# R7FA2A1AB register map
Vendor: Renesas; Series: RA2; File version: 1.1
CPU: CM23 r1p0, little endian, MPU, no FPU, VTOR, 2 interrupt priority bits
Registers are 8-bit, read-write, reset 0x0 unless marked. A register's access mark holds for its fields unless they carry their own. Offsets are from the block's base; [hi:lo] are bit positions; {n}, {i} and the like mark numbered series; 'fields as' and 'values as' point back to an identical list.

## CAN0 — CAN0 Module
Base 0x40050000
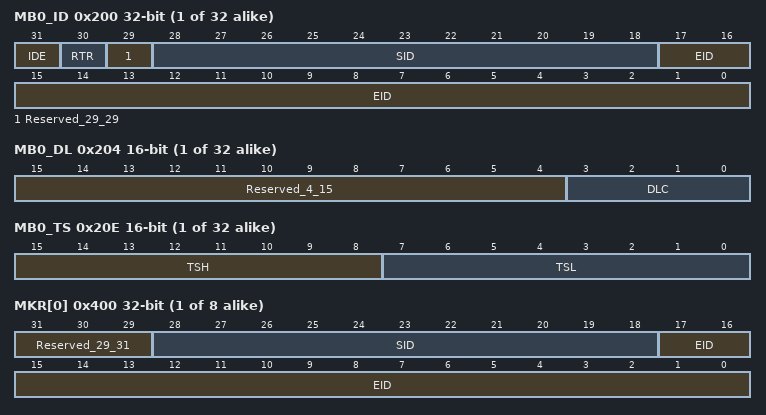
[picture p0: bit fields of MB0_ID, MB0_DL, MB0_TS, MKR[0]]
{0x200+0x10*i} MB{i}_ID (i=0..31) 32-bit reset not defined — Mailbox Register
  [31] IDE — ID Extension
  [30] RTR — Remote Transmission Request
  [29] Reserved_29_29 — This bit is read as 0. The write value should be 0.
  [28:18] SID — Standard ID
  [17:0] EID — Extended ID
{0x204+0x10*i} MB{i}_DL (i=0..31) 16-bit reset not defined — Mailbox Register
  [15:4] Reserved_4_15 — These bits are read as 000000000000. The write value should be 000000000000.
  [3:0] DLC — Data Length Code
{0x206+0x10*i} MB{i}_D0 (i=0..31) reset not defined — Mailbox Register
  [7:0] DATA0 — Data Bytes 0.DATA0 store the transmitted or received CAN message data. Transmission or reception starts from DATA0. The bit order on the CAN bus is MSB first, and transmission or reception starts from bit 7.
{0x207+0x10*i} MB{i}_D1 (i=0..31) reset not defined — Mailbox Register
  [7:0] DATA1 — Data Bytes 1DATA1 store the transmitted or received CAN message data. Transmission or reception starts from DATA0. The bit order on the CAN bus is MSB first, and transmission or reception starts from bit 7.
{0x208+0x10*i} MB{i}_D2 (i=0..31) reset not defined — Mailbox Register
  [7:0] DATA2 — Data Bytes 2DATA2 store the transmitted or received CAN message data. Transmission or reception starts from DATA0. The bit order on the CAN bus is MSB first, and transmission or reception starts from bit 7.
{0x209+0x10*i} MB{i}_D3 (i=0..31) reset not defined — Mailbox Register
  [7:0] DATA3 — Data Bytes 3DATA3 store the transmitted or received CAN message data. Transmission or reception starts from DATA0. The bit order on the CAN bus is MSB first, and transmission or reception starts from bit 7.
{0x20A+0x10*i} MB{i}_D4 (i=0..31) reset not defined — Mailbox Register
  [7:0] DATA4 — Data Bytes 4DATA4 store the transmitted or received CAN message data. Transmission or reception starts from DATA0. The bit order on the CAN bus is MSB first, and transmission or reception starts from bit 7.
{0x20B+0x10*i} MB{i}_D5 (i=0..31) reset not defined — Mailbox Register
  [7:0] DATA5 — Data Bytes 5DATA5 store the transmitted or received CAN message data. Transmission or reception starts from DATA0. The bit order on the CAN bus is MSB first, and transmission or reception starts from bit 7.
{0x20C+0x10*i} MB{i}_D6 (i=0..31) reset not defined — Mailbox Register
  [7:0] DATA6 — Data Bytes 6DATA6 store the transmitted or received CAN message data. Transmission or reception starts from DATA0. The bit order on the CAN bus is MSB first, and transmission or reception starts from bit 7.
{0x20D+0x10*i} MB{i}_D7 (i=0..31) reset not defined — Mailbox Register
  [7:0] DATA7 — Data Bytes 7DATA7 store the transmitted or received CAN message data. Transmission or reception starts from DATA0. The bit order on the CAN bus is MSB first, and transmission or reception starts from bit 7.
{0x20E+0x10*i} MB{i}_TS (i=0..31) 16-bit reset not defined — Mailbox Register
  [15:8] TSH — Time Stamp Lower ByteBits TSH[7:0] store the counter value of the time stamp when received messages are stored in the mailbox.
  [7:0] TSL — Time Stamp Higher ByteBits TSL[7:0] store the counter value of the time stamp when received messages are stored in the mailbox.
{0x400+4i} MKR[{i}] (i=0..7) 32-bit reset not defined — Mask Register
  [31:29] Reserved_29_31 — These bits are read as 000. The write value should be 000.
  [28:18] SID — Standard ID
  [17:0] EID — Extended ID
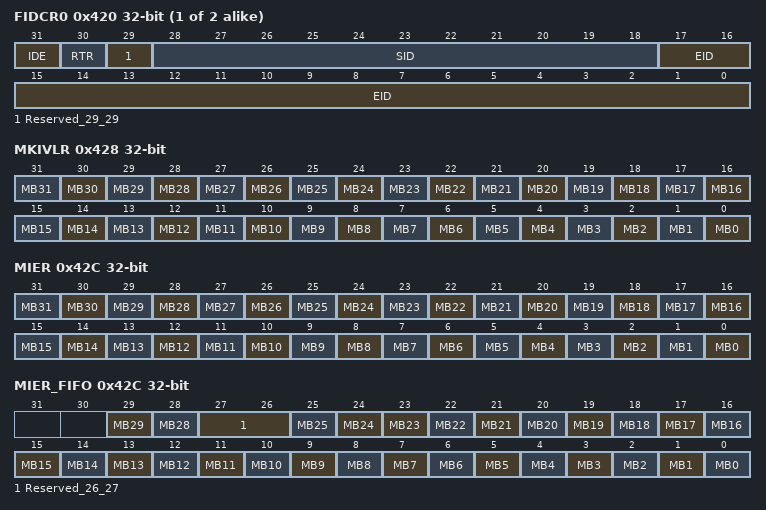
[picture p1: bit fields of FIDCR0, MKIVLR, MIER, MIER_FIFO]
{0x420+4i} FIDCR{i} (i=0..1) 32-bit reset not defined — FIFO Received ID Compare Registers
  fields as MB0_ID
0x428 MKIVLR 32-bit reset not defined — Mask Invalid Register
  [n] MB{n} (n=0..31) — mailbox {n} Mask Invalid
0x42C MIER 32-bit reset not defined — Mailbox Interrupt Enable Register (Normal mailbox mode)
  [n] MB{n} (n=0..31) — mailbox {n} Interrupt Enable
0x42C MIER_FIFO 32-bit reset not defined (alternate view of MIER) — Mailbox Interrupt Enable Register(FIFO mailbox mode)
  [29] MB29 — Receive FIFO Interrupt Generation Timing Control
  [28] MB28 — Receive FIFO Interrupt Enable
  [27:26] Reserved_26_27 — These bits are read as 00. The write value should be 00.
  [25] MB25 — Transmit FIFO Interrupt Generation Timing Control
  [24] MB24 — Transmit FIFO Interrupt Enable
  [n] MB{n} (n=0..23) — mailbox {n} Interrupt Enable
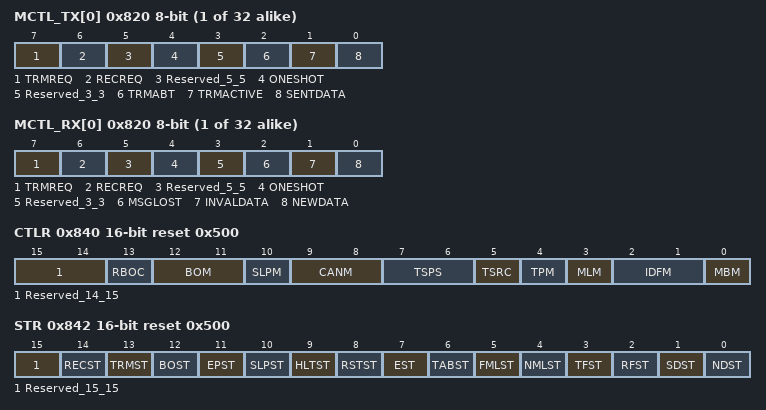
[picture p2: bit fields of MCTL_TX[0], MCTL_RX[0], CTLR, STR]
{0x820+i} MCTL_TX[{i}] (i=0..31) — Message Control Register(Transmit mode (when the TRMREQ bit is 1 and the RECREQ bit is 0))
  [7] TRMREQ — Transmit Mailbox Request
  [6] RECREQ — Receive Mailbox Request
  [5] Reserved_5_5 — This bit is read as 0. The write value should be 0.
  [4] ONESHOT — One,Shot Enable
  [3] Reserved_3_3 — This bit is read as 0. The write value should be 0.
  [2] TRMABT — Transmission Abort Complete Flag (Transmit mailbox setting enabled)
  [1] TRMACTIVE ro — Transmission,in,Progress Status Flag (Transmit mailbox setting enabled)
  [0] SENTDATA — Transmission Complete Flag
{0x820+i} MCTL_RX[{i}] (i=0..31) (alternate view of MCTL_TX[{i}]) — Message Control Register( Receive mode (when the TRMREQ bit is 0 and the RECREQ bit is 1))
  [7] TRMREQ — Transmit Mailbox Request
  [6] RECREQ — Receive Mailbox Request
  [5] Reserved_5_5 — This bit is read as 0. The write value should be 0.
  [4] ONESHOT — One,Shot Enable
  [3] Reserved_3_3 — This bit is read as 0. The write value should be 0.
  [2] MSGLOST — Message Lost Flag(Receive mailbox setting enabled)
  [1] INVALDATA ro — Reception,in,Progress Status Flag (Receive mailbox setting enabled)
  [0] NEWDATA — Reception Complete Flag
0x840 CTLR 16-bit reset 0x500 — Control Register
  [15:14] Reserved_14_15 — These bits are read as 00. The write value should be 00.
  [13] RBOC — Forcible Return From Bus,Off
  [12:11] BOM — Bus,Off Recovery Mode
  [10] SLPM — CAN Sleep Mode
  [9:8] CANM — CAN Mode of Operation Select
  [7:6] TSPS — Time Stamp Prescaler Select
  [5] TSRC — Time Stamp Counter Reset Command
  [4] TPM — Transmission Priority Mode Select
  [3] MLM — Message Lost Mode Select
  [2:1] IDFM — ID Format Mode Select
  [0] MBM — CAN Mailbox Mode Select
0x842 STR 16-bit ro reset 0x500 — Status Register
  [15] Reserved_15_15 — This bit is read as 0.
  [14] RECST — Receive Status Flag (receiver)
  [13] TRMST — Transmit Status Flag (transmitter)
  [12] BOST — Bus,Off Status Flag
  [11] EPST — Error,Passive Status Flag
  [10] SLPST — CAN Sleep Status Flag
  [9] HLTST — CAN Halt Status Flag
  [8] RSTST — CAN Reset Status Flag
  [7] EST — Error Status Flag
  [6] TABST — Transmission Abort Status Flag
  [5] FMLST — FIFO Mailbox Message Lost Status Flag
  [4] NMLST — Normal Mailbox Message Lost Status Flag
  [3] TFST — Transmit FIFO Status Flag
  [2] RFST — Receive FIFO Status Flag
  [1] SDST — SENTDATA Status Flag
  [0] NDST — NEWDATA Status Flag
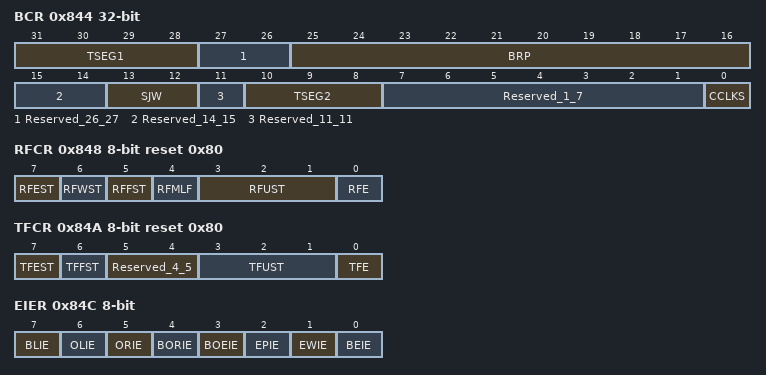
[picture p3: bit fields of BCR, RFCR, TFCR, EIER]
0x844 BCR 32-bit — Bit Configuration Register
  [31:28] TSEG1 — Time Segment 1 Control
  [27:26] Reserved_26_27 — These bits are read as 00. The write value should be 00.
  [25:16] BRP — Baud Rate Prescaler select . These bits set the frequency of the CAN communication clock (fCANCLK).
  [15:14] Reserved_14_15 — These bits are read as 00. The write value should be 00.
  [13:12] SJW — Resynchronization Jump Width Control
  [11] Reserved_11_11 — This bit is read as 0. The write value should be 0.
  [10:8] TSEG2 — Time Segment 2 Control
  [7:1] Reserved_1_7 — These bits are read as 0000000. The write value should be 0000000.
  [0] CCLKS — CAN Clock Source Selection
0x848 RFCR reset 0x80 — Receive FIFO Control Register
  [7] RFEST ro — Receive FIFO Empty Status Flag
  [6] RFWST ro — Receive FIFO Buffer Warning Status Flag
  [5] RFFST ro — Receive FIFO Full Status Flag
  [4] RFMLF — Receive FIFO Message Lost Flag
  [3:1] RFUST ro — Receive FIFO Unread Message Number Status
  [0] RFE — Receive FIFO Enable
0x849 RFPCR wo reset not defined — Receive FIFO Pointer Control Register
  [7:0] RFPCR — The CPU,side pointer for the receive FIFO is incremented by writing FFh to RFPCR.
0x84A TFCR reset 0x80 — Transmit FIFO Control Register
  [7] TFEST ro — Transmit FIFO Empty Status
  [6] TFFST ro — Transmit FIFO Full Status
  [5:4] Reserved_4_5 — These bits are read as 00. The write value should be 00.
  [3:1] TFUST ro — Transmit FIFO Unsent Message Number Status
  [0] TFE — Transmit FIFO Enable
0x84B TFPCR wo reset not defined — Transmit FIFO Pointer Control Register
  [7:0] TFPCR — The CPU,side pointer for the transmit FIFO is incremented by writing FFh to TFPCR.
0x84C EIER — Error Interrupt Enable Register
  [7] BLIE — Bus Lock Interrupt Enable
  [6] OLIE — Overload Frame Transmit Interrupt Enable
  [5] ORIE — Overrun Interrupt Enable
  [4] BORIE — Bus,Off Recovery Interrupt Enable
  [3] BOEIE — Bus,Off Entry Interrupt Enable
  [2] EPIE — Error,Passive Interrupt Enable
  [1] EWIE — Error,Warning Interrupt Enable
  [0] BEIE — Bus Error Interrupt Enable
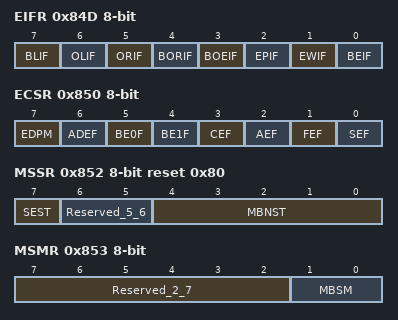
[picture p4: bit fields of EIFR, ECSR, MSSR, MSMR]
0x84D EIFR — Error Interrupt Factor Judge Register
  [7] BLIF — Bus Lock Detect Flag
  [6] OLIF — Overload Frame Transmission Detect Flag
  [5] ORIF — Receive Overrun Detect Flag
  [4] BORIF — Bus,Off Recovery Detect Flag
  [3] BOEIF — Bus,Off Entry Detect Flag
  [2] EPIF — Error,Passive Detect Flag
  [1] EWIF — Error,Warning Detect Flag
  [0] BEIF — Bus Error Detect Flag
0x84E RECR ro — Receive Error Count Register
  [7:0] RECR — Receive error count functionRECR increments or decrements the counter value according to the error status of the CAN module during reception.
0x84F TECR ro — Transmit Error Count Register
  [7:0] TECR — Transmit error count functionTECR increments or decrements the counter value according to the error status of the CAN module during transmission.
0x850 ECSR — Error Code Store Register
  [7] EDPM — Error Display Mode Select
  [6] ADEF — ACK Delimiter Error Flag
  [5] BE0F — Bit Error (dominant) Flag
  [4] BE1F — Bit Error (recessive) Flag
  [3] CEF — CRC Error Flag
  [2] AEF — ACK Error Flag
  [1] FEF — Form Error Flag
  [0] SEF — Stuff Error Flag
0x851 CSSR reset not defined — Channel Search Support Register
  [7:0] CSSR — When the value for the channel search is input, the channel number is output to MSSR.
0x852 MSSR ro reset 0x80 — Mailbox Search Status Register
  [7] SEST — Search Result Status
  [6:5] Reserved_5_6 — These bits are read as 00.
  [4:0] MBNST — Search Result Mailbox Number Status These bits output the smallest mailbox number that is searched in each mode of MSMR.
0x853 MSMR — Mailbox Search Mode Register
  [7:2] Reserved_2_7 — These bits are read as 000000. The write value should be 000000.
  [1:0] MBSM — Mailbox Search Mode Select
0x854 TSR 16-bit ro — Time Stamp Register
  [15:0] TSR — Free,running counter value for the time stamp function
0x856 AFSR 16-bit reset not defined — Acceptance Filter Support Register
  [15:0] AFSR — After the standard ID of a received message is written, the value converted for data table search can be read.
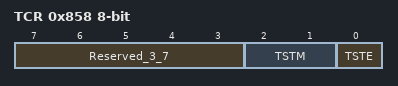
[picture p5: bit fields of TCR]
0x858 TCR — Test Control Register
  [7:3] Reserved_3_7 — These bits are read as 00000. The write value should be 00000.
  [2:1] TSTM — CAN Test Mode Select
  [0] TSTE — CAN Test Mode Enable
